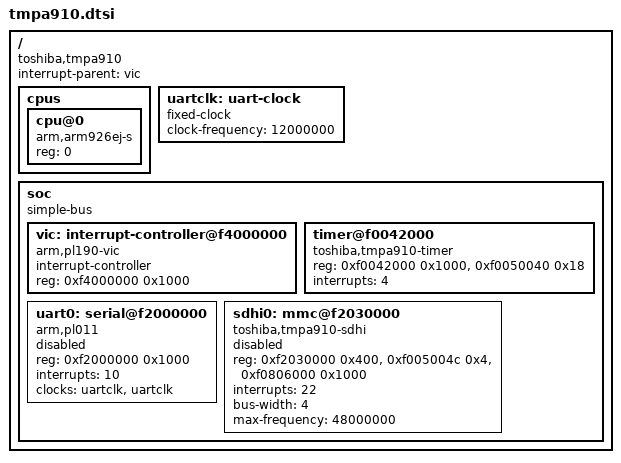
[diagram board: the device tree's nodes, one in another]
// SPDX-License-Identifier: GPL-2.0-only
/*
 * Toshiba TMPA910 description, based on MuCross Linux 2.6.36:
 * https://mucross.com/downloads/tx09-linux/Release-20110309/src/
 * Copyright (C) 2010 Thomas Haase (Thomas.Haase@web.de)
 */
#include <dt-bindings/interrupt-controller/irq.h>
/ {
	#address-cells = <1>;
	#size-cells = <1>;
	compatible = "toshiba,tmpa910";
	interrupt-parent = <&vic>;

	cpus {
		#address-cells = <1>;
		#size-cells = <0>;
		cpu@0 {
			compatible = "arm,arm926ej-s";
			device_type = "cpu";
			reg = <0>;
		};
	};

	uartclk: uart-clock {
		compatible = "fixed-clock";
		#clock-cells = <0>;
		clock-frequency = <12000000>;
	};

	soc {
		compatible = "simple-bus";
		#address-cells = <1>;
		#size-cells = <1>;
		ranges;

		vic: interrupt-controller@f4000000 {
			compatible = "arm,pl190-vic";
			interrupt-controller;
			#interrupt-cells = <1>;
			reg = <0xf4000000 0x1000>;
		};

		timer@f0042000 {
			compatible = "toshiba,tmpa910-timer";
			reg = <0xf0042000 0x1000>, <0xf0050040 0x18>;
			reg-names = "timer", "clock-control";
			interrupts = <4>;
		};

		uart0: serial@f2000000 {
			compatible = "arm,pl011", "arm,primecell";
			reg = <0xf2000000 0x1000>;
			interrupts = <10>;
			clocks = <&uartclk>, <&uartclk>;
			clock-names = "uartclk", "apb_pclk";
			status = "disabled";
		};


		sdhi0: mmc@f2030000 {
			compatible = "toshiba,tmpa910-sdhi";
			reg = <0xf2030000 0x400>,
			      <0xf005004c 0x4>,
			      <0xf0806000 0x1000>;
			reg-names = "sdhi", "clock-control", "port-g";
			interrupts = <22>;
			bus-width = <4>;
			max-frequency = <48000000>;
			status = "disabled";
		};
	};
};
